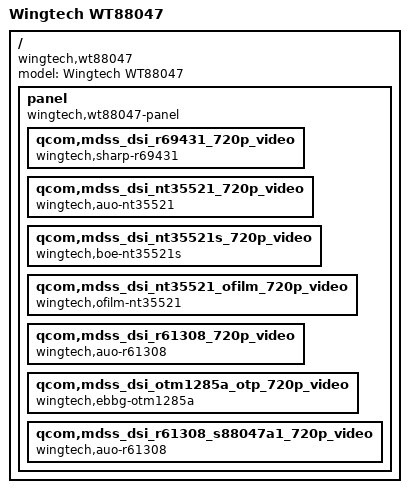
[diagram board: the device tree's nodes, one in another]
// SPDX-License-Identifier: GPL-2.0-only

/dts-v1/;

/include/ "skeleton.dtsi"

/ {
	/* FIXME: Need to split this up if there are more devices with same board-id */
	compatible = "wingtech,wt88047", "qcom,msm8916-v1-qrd/12-v1",
		     "qcom,msm8916", "lk2nd,device";
	model = "Wingtech WT88047";

	panel {
		compatible = "wingtech,wt88047-panel";

		qcom,mdss_dsi_r69431_720p_video {
			compatible = "wingtech,sharp-r69431";
		};
		qcom,mdss_dsi_nt35521_720p_video {
			compatible = "wingtech,auo-nt35521";
		};
		qcom,mdss_dsi_nt35521s_720p_video {
			compatible = "wingtech,boe-nt35521s";
		};
		qcom,mdss_dsi_nt35521_ofilm_720p_video {
			compatible = "wingtech,ofilm-nt35521";
		};
		/* qcom,mdss_dsi_otm1285a_720p_video is not supported */
		qcom,mdss_dsi_r61308_720p_video {
			compatible = "wingtech,auo-r61308";
		};
		qcom,mdss_dsi_otm1285a_otp_720p_video {
			compatible = "wingtech,ebbg-otm1285a";
		};
		qcom,mdss_dsi_r61308_s88047a1_720p_video {
			compatible = "wingtech,auo-r61308";
		};
	};
};
